# STM32H523 register map
File version: 1.3
CPU: CM33 r0p0, little endian, MPU, FPU, 4 interrupt priority bits
Registers are 32-bit, read-write, reset 0x0 unless marked. A register's access mark holds for its fields unless they carry their own. Offsets are from the block's base; [hi:lo] are bit positions; {n}, {i} and the like mark numbered series.

## DCMI — DCMI address block description
Base 0x4202C000
Same registers: DCMI_S 0x5202C000
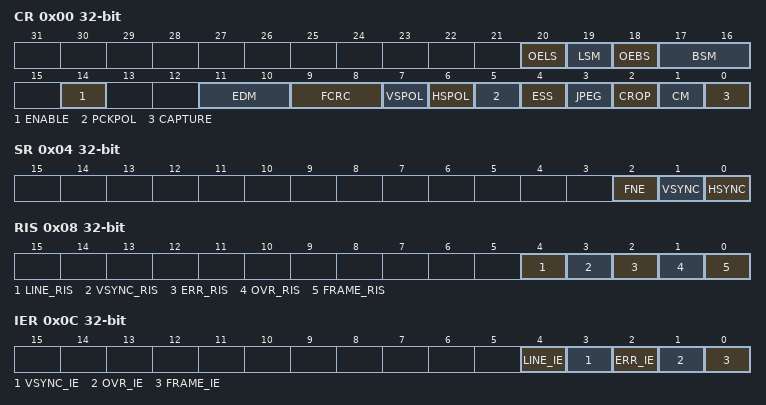
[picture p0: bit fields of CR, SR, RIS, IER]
0x00 CR — DCMI control register
  [20] OELS — Odd/Even Line Select (Line Select Start)
    0=Odd (Interface captures first line after the frame start, second one being dropped); 1=Even (Interface captures second line from the frame start, first one being dropped)
  [19] LSM — Line Select mode
    0=All (Interface captures all received lines); 1=Half (Interface captures one line out of two)
  [18] OEBS — Odd/Even Byte Select (Byte Select Start)
    0=Odd (Interface captures first data (byte or double byte) from the frame/line start, second one being dropped); 1=Even (Interface captures second data (byte or double byte) from the frame/line start, first one being dropped)
  [17:16] BSM — Byte Select mode
    0=All (Interface captures all received data); 1=EveryOther (Interface captures every other byte from the received data); 2=Fourth (Interface captures one byte out of four); 3=TwoOfFour (Interface captures two bytes out of four)
  [14] ENABLE — DCMI enable
    0=Disabled (DCMI disabled); 1=Enabled (DCMI enabled)
  [11:10] EDM — Extended data mode
    0=BitWidth8 (Interface captures 8-bit data on every pixel clock); 1=BitWidth10 (Interface captures 10-bit data on every pixel clock); 2=BitWidth12 (Interface captures 12-bit data on every pixel clock); 3=BitWidth14 (Interface captures 14-bit data on every pixel clock)
  [9:8] FCRC — Frame capture rate control
    0=All (All frames are captured); 1=Alternate (Every alternate frame captured (50% bandwidth reduction)); 2=OneOfFour (One frame out of four captured (75% bandwidth reduction))
  [7] VSPOL — Vertical synchronization polarity
    0=ActiveLow (DCMI_VSYNC active low); 1=ActiveHigh (DCMI_VSYNC active high)
  [6] HSPOL — Horizontal synchronization polarity
    0=ActiveLow (DCMI_HSYNC active low); 1=ActiveHigh (DCMI_HSYNC active high)
  [5] PCKPOL — Pixel clock polarity
    0=Falling edge active; 1=Rising edge active
  [4] ESS — Embedded synchronization select
    0=Hardware synchronization data capture (frame/line start/stop) is synchronized with the DCMI_HSYNC/DCMI_VSYNC signals; 1=Embedded synchronization data capture is synchronized with synchronization codes embedded in the data flow
  [3] JPEG — JPEG format
    0=Uncompressed video format; 1=JPEG (This bit is used for JPEG data transfers. The DCMI_HSYNC signal is used as data enable. The crop and embedded synchronization features (ESS bit) cannot be used in this mode)
  [2] CROP — Crop feature
    0=Full (The full image is captured. In this case the total number of bytes in an image frame must be a multiple of four); 1=Cropped (Only the data inside the window specified by the crop register is captured. If the size of the crop window exceeds the picture size, then only the picture size is captured)
  [1] CM — Capture mode
    0=Continuous grab mode - The received data are transferred into the destination memory through the DMA. The buffer location and mode (linear or circular buffer) is controlled through the system DMA; 1=Snapshot mode (single frame) - Once activated, the interface waits for the start of frame and then transfers a single frame through the DMA. At the end of the frame, the CAPTURE bit is automatically reset
  [0] CAPTURE — Capture enable
    0=Disabled (Capture disabled); 1=Enabled (Capture enabled)
0x04 SR ro — DCMI status register
  [2] FNE — FIFO not empty
    0=NotEmpty (FIFO contains valid data); 1=Empty (FIFO empty)
  [1] VSYNC — Vertical synchronization
    0=ActiveFrame; 1=BetweenFrames (Synchronization between frames)
  [0] HSYNC — Horizontal synchronization
    0=ActiveLine; 1=BetweenLines (Synchronization between lines)
0x08 RIS ro — DCMI raw interrupt status register
  [4] LINE_RIS — Line raw interrupt status
    0=Cleared (Interrupt cleared); 1=Set (Interrupt set)
  [3] VSYNC_RIS — DCMI_VSYNC raw interrupt status
    0=Cleared (Interrupt cleared); 1=Set (Interrupt set)
  [2] ERR_RIS — Synchronization error raw interrupt status
    0=NoError (No synchronization error detected); 1=SynchronizationError (Embedded synchronization characters are not received in the correct order)
  [1] OVR_RIS — Overrun raw interrupt status
    0=NoOverrun (No data buffer overrun occurred); 1=OverrunOccured (A data buffer overrun occurred and the data FIFO is corrupted. The bit is cleared by setting the OVR_ISC bit of the DCMI_ICR register)
  [0] FRAME_RIS — Capture complete raw interrupt status
    0=NoNewCapture; 1=FrameCaptured (A frame has been captured)
0x0C IER — DCMI interrupt enable register
  [4] LINE_IE — Line interrupt enable
    0=Disabled (No interrupt generation when the line is received); 1=Enabled (An Interrupt is generated when a line has been completely received)
  [3] VSYNC_IE — DCMI_VSYNC interrupt enable
    0=Disabled (No interrupt generation); 1=Enabled (An interrupt is generated on each DCMI_VSYNC transition from the inactive to the active state)
  [2] ERR_IE — Synchronization error interrupt enable
    0=Disabled (No interrupt generation); 1=Enabled (An interrupt is generated if the embedded synchronization codes are not received in the correct order)
  [1] OVR_IE — Overrun interrupt enable
    0=Disabled (No interrupt generation); 1=Enabled (An interrupt is generated if the DMA was not able to transfer the last data before new data (32-bit) are received)
  [0] FRAME_IE — Capture complete interrupt enable
    0=Disabled (No interrupt generation); 1=Enabled (An interrupt is generated at the end of each received frame/crop window (in crop mode))
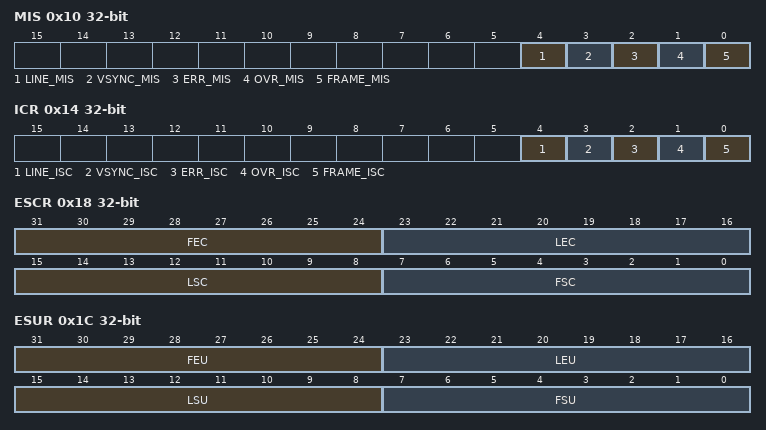
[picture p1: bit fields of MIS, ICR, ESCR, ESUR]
0x10 MIS ro — DCMI masked interrupt status register
  [4] LINE_MIS — Line masked interrupt status
    0=Disabled (No interrupt generation when the line is received); 1=Enabled (An Interrupt is generated when a line has been completely received and the LINE_IE bit is set in DCMI_IER)
  [3] VSYNC_MIS — VSYNC masked interrupt status
    0=Disabled (No interrupt is generated on DCMI_VSYNC transitions); 1=Enabled (An interrupt is generated on each DCMI_VSYNC transition from the inactive to the active state and the VSYNC_IE bit is set in DCMI_IER)
  [2] ERR_MIS — Synchronization error masked interrupt status
    0=Disabled (No interrupt is generated on a synchronization error); 1=Enabled (An interrupt is generated if the embedded synchronization codes are not received in the correct order and the ERR_IE bit in DCMI_IER is set)
  [1] OVR_MIS — Overrun masked interrupt status
    0=Disabled (No interrupt is generated on overrun); 1=Enabled (An interrupt is generated if the DMA was not able to transfer the last data before new data (32-bit) are received and the OVR_IE bit is set in DCMI_IER)
  [0] FRAME_MIS — Capture complete masked interrupt status
    0=Disabled (No interrupt is generated after a complete capture); 1=Enabled (An interrupt is generated at the end of each received frame/crop window (in crop mode) and the FRAME_IE bit is set in DCMI_IER)
0x14 ICR wo — DCMI interrupt clear register
  [4] LINE_ISC — line interrupt status clear
    1=Clear (Setting this bit clears the LINE_RIS flag in the DCMI_RIS register)
  [3] VSYNC_ISC — Vertical Synchronization interrupt status clear
    1=Clear (Setting this bit clears the VSYNC_RIS flag in the DCMI_RIS register)
  [2] ERR_ISC — Synchronization error interrupt status clear
    1=Clear (Setting this bit clears the ERR_RIS flag in the DCMI_RIS register)
  [1] OVR_ISC — Overrun interrupt status clear
    1=Clear (Setting this bit clears the OVR_RIS flag in the DCMI_RIS register)
  [0] FRAME_ISC — Capture complete interrupt status clear
    1=Clear (Setting this bit clears the FRAME_RIS flag in the DCMI_RIS register)
0x18 ESCR — DCMI embedded synchronization code register
  [31:24] FEC — Frame end delimiter code
  [23:16] LEC — Line end delimiter code
  [15:8] LSC — Line start delimiter code
  [7:0] FSC — Frame start delimiter code
0x1C ESUR — DCMI embedded synchronization unmask register
  [31:24] FEU — Frame end delimiter unmask
  [23:16] LEU — Line end delimiter unmask
  [15:8] LSU — Line start delimiter unmask
  [7:0] FSU — Frame start delimiter unmask
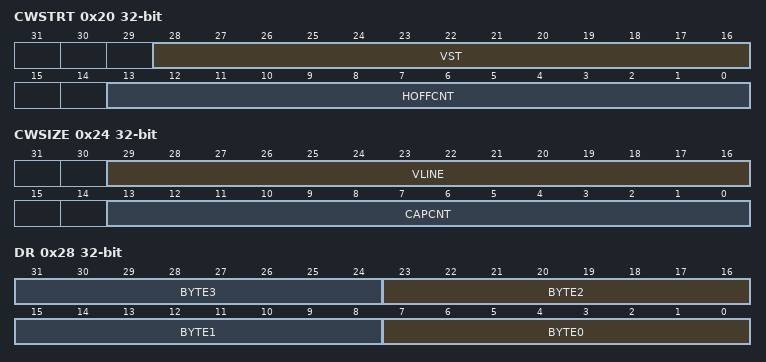
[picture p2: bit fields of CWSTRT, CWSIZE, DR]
0x20 CWSTRT — DCMI crop window start
  [28:16] VST — Vertical start line count
  [13:0] HOFFCNT — Horizontal offset count
0x24 CWSIZE — DCMI crop window size
  [29:16] VLINE — Vertical line count
  [13:0] CAPCNT — Capture count
0x28 DR ro — DCMI data register
  [8n+7:8n] BYTE{n} (n=0..3) — Data byte {n}
